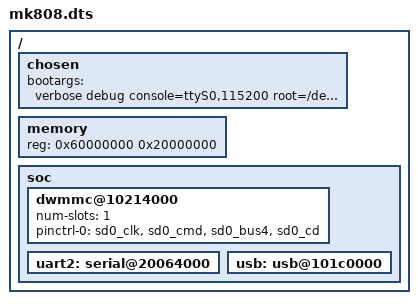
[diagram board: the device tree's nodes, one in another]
/dts-v1/;
#include "rk3066a.dtsi"

/ {
	chosen {
		bootargs = "verbose debug console=ttyS0,115200 root=/dev/mmcblk0p1 rootwait";
	};

	memory {
		reg = <0x60000000 0x20000000>;
	};

	soc {

		dwmmc@10214000 {
			num-slots = <1>;
			status = "okay";
			pinctrl-names = "default";
			pinctrl-0 = <&sd0_clk &sd0_cmd &sd0_bus4 &sd0_cd>;
		};

		uart2: serial@20064000 {
			status = "okay";
		};

		usb: usb@101c0000 {
			status = "okay";
		};

	};
};
